# STM32H7R register map
File version: 1.0
CPU: CM7 r0p1, little endian, MPU, FPU, 4 interrupt priority bits
Registers are 32-bit, read-write, reset 0x0 unless marked. A register's access mark holds for its fields unless they carry their own. Offsets are from the block's base; [hi:lo] are bit positions; {n}, {i} and the like mark numbered series; 'fields as' and 'values as' point back to an identical list.

## LTDC — LTDC register block
Base 0x50001000
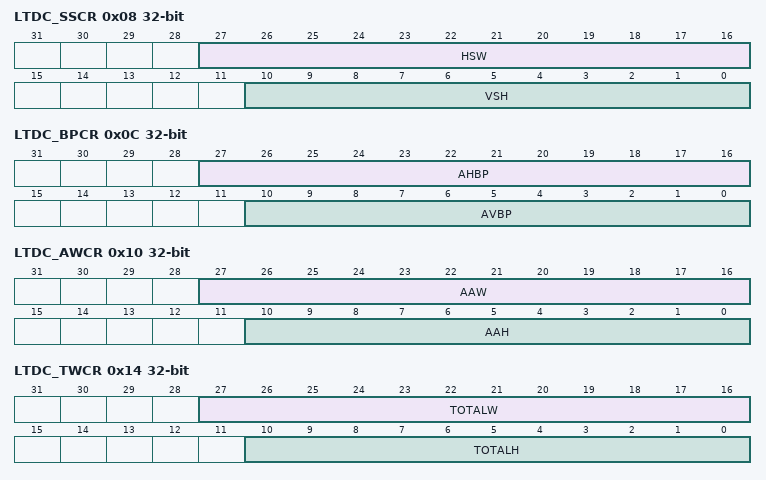
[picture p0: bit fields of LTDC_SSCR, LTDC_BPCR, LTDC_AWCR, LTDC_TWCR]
0x08 LTDC_SSCR — LTDC synchronization size configuration register
  [27:16] HSW — horizontal synchronization width (in units of pixel clock period) These bits define the number of Horizontal Synchronization pixel minus 1.
  [10:0] VSH — vertical synchronization height (in units of horizontal scan line) These bits define the vertical Synchronization height minus 1. It represents the number of horizontal synchronization lines.
0x0C LTDC_BPCR — LTDC back porch configuration register
  [27:16] AHBP — accumulated horizontal back porch (in units of pixel clock period) These bits define the accumulated horizontal back porch width that includes the horizontal synchronization and horizontal back porch pixels minus 1. The horizontal back porch is the period between horizontal synchronization going inactive and the start of the active display part of the next scan line.
  [10:0] AVBP — accumulated Vertical back porch (in units of horizontal scan line) These bits define the accumulated vertical back porch width that includes the vertical synchronization and vertical back porch lines minus 1. The vertical back porch is the number of horizontal scan lines at a start of frame to the start of the first active scan line of the next frame.
0x10 LTDC_AWCR — LTDC active width configuration register
  [27:16] AAW — accumulated active width (in units of pixel clock period) These bits define the accumulated active width which includes the horizontal synchronization, horizontal back porch and active pixels minus 1. The active width is the number of pixels in active display area of the panel scan line. Refer to device datasheet for maximum active width supported following maximum pixel clock.
  [10:0] AAH — accumulated active height (in units of horizontal scan line) These bits define the accumulated height which includes the vertical synchronization, vertical back porch and the active height lines minus 1. The active height is the number of active lines in the panel. Refer to device datasheet for maximum active height supported following maximum pixel clock.
0x14 LTDC_TWCR — LTDC total width configuration register
  [27:16] TOTALW — total width (in units of pixel clock period) These bits defines the accumulated total width which includes the horizontal synchronization, horizontal back porch, active width and horizontal front porch pixels minus 1.
  [10:0] TOTALH — total height (in units of horizontal scan line) These bits defines the accumulated height which includes the vertical synchronization, vertical back porch, the active height and vertical front porch height lines minus 1.
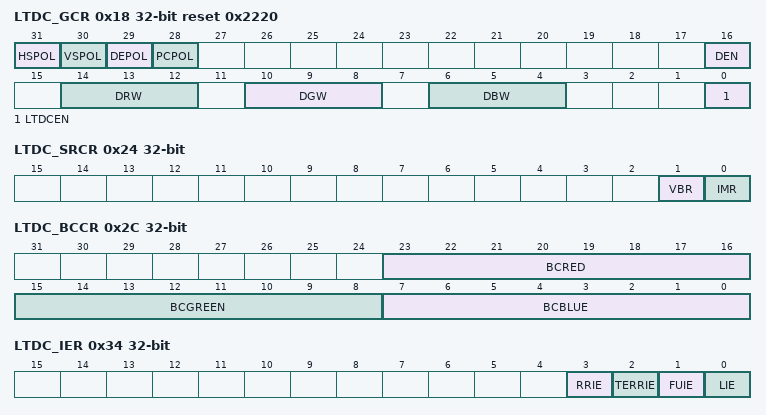
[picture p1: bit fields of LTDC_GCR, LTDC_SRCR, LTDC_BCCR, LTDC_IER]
0x18 LTDC_GCR access per field reset 0x2220 — LTDC global control register
  [31] HSPOL rw — horizontal synchronization polarity This bit is set and cleared by software.
    0=horizontal synchronization polarity is active low; 1=horizontal synchronization polarity is active high
  [30] VSPOL rw — vertical synchronization polarity This bit is set and cleared by software.
    0=vertical synchronization is active low; 1=vertical synchronization is active high
  [29] DEPOL rw — not data enable polarity This bit is set and cleared by software.
    0=not data enable polarity is active low; 1=not data enable polarity is active high
  [28] PCPOL rw — pixel clock polarity This bit is set and cleared by software.
    0=pixel clock polarity is active low; 1=pixel clock is active high
  [16] DEN rw — dither enable This bit is set and cleared by software.
    0=dither disabled; 1=dither enabled
  [14:12] DRW ro — dither red width These bits return the Dither Red Bits.
  [10:8] DGW ro — dither green width These bits return the dither green bits.
  [6:4] DBW ro — dither blue width These bits return the dither blue bits.
  [0] LTDCEN rw — LCD-TFT controller enable This bit is set and cleared by software.
    0=LTDC disabled; 1=LTDC enabled
0x24 LTDC_SRCR — LTDC shadow reload configuration register
  [1] VBR — vertical blanking reload This bit is set by software and cleared only by hardware after reload (it cannot be cleared through register write once it is set).
    0=no effect; 1=The shadow registers are reloaded during the vertical blanking period (at the beginning of the first line after the active display area)
  [0] IMR — immediate reload This bit is set by software and cleared only by hardware after reload.
    0=no effect; 1=The shadow registers are reloaded immediately
0x2C LTDC_BCCR — LTDC background color configuration register
  [23:16] BCRED — background color red value These bits configure the background red value.
  [15:8] BCGREEN — background color green value These bits configure the background green value.
  [7:0] BCBLUE — background color blue value These bits configure the background blue value.
0x34 LTDC_IER — LTDC interrupt enable register
  [3] RRIE — register reload interrupt enable This bit is set and cleared by software.
    0=register reload interrupt disable; 1=register reload interrupt enable
  [2] TERRIE — transfer error interrupt enable This bit is set and cleared by software.
    0=transfer error interrupt disable; 1=transfer error interrupt enable
  [1] FUIE — FIFO underrun interrupt enable This bit is set and cleared by software.
    0=FIFO underrun interrupt disable; 1=FIFO underrun Interrupt enable
  [0] LIE — line interrupt enable This bit is set and cleared by software.
    0=line interrupt disable; 1=line interrupt enable
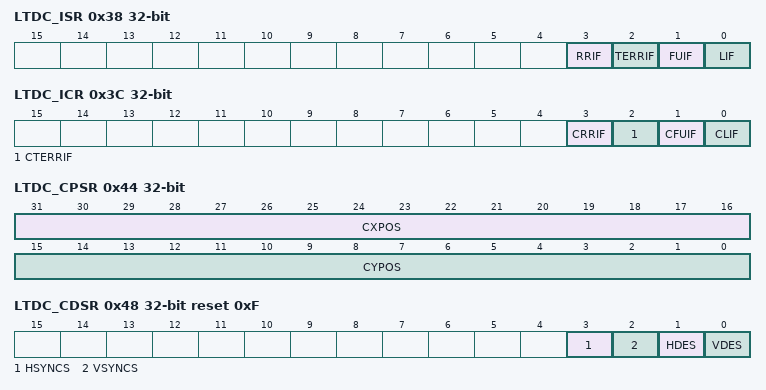
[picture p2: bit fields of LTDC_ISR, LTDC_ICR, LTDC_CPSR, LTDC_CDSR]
0x38 LTDC_ISR ro — LTDC interrupt status register
  [3] RRIF — register reload interrupt flag
    0=no register reload interrupt generated; 1=register reload interrupt generated when a vertical blanking reload occurs (and the first line after the active area is reached)
  [2] TERRIF — transfer error interrupt flag
    0=no transfer error interrupt generated; 1=transfer error interrupt generated when a bus error occurs
  [1] FUIF — FIFO underrun interrupt flag
    0=no FIFO underrun interrupt generated; 1=FIFO underrun interrupt generated, if one of the layer FIFOs is empty and pixel data is read from the FIFO
  [0] LIF — line interrupt flag
    0=no line interrupt generated; 1=line interrupt generated when a programmed line is reached
0x3C LTDC_ICR wo — LTDC interrupt clear register
  [3] CRRIF — clears register reload interrupt flag
    0=no effect; 1=clears the RRIF flag in the LTDC_ISR register
  [2] CTERRIF — clears the transfer error interrupt flag
    0=no effect; 1=clears the TERRIF flag in the LTDC_ISR register
  [1] CFUIF — clears the FIFO underrun interrupt flag
    0=no effect; 1=clears the FUDERRIF flag in the LTDC_ISR register
  [0] CLIF — clears the line interrupt flag
    0=no effect; 1=clears the LIF flag in the LTDC_ISR register
0x40 LTDC_LIPCR — LTDC line interrupt position configuration register
  [10:0] LIPOS — line interrupt position These bits configure the line interrupt position.
0x44 LTDC_CPSR ro — LTDC current position status register
  [31:16] CXPOS — current X position These bits return the current X position.
  [15:0] CYPOS — current Y position These bits return the current Y position.
0x48 LTDC_CDSR ro reset 0xF — LTDC current display status register
  [all] fields
    0=active low; 1=active high
  [3] HSYNCS — horizontal synchronization display status
  [2] VSYNCS — vertical synchronization display status
  [1] HDES — horizontal data enable display status
  [0] VDES — vertical data enable display status
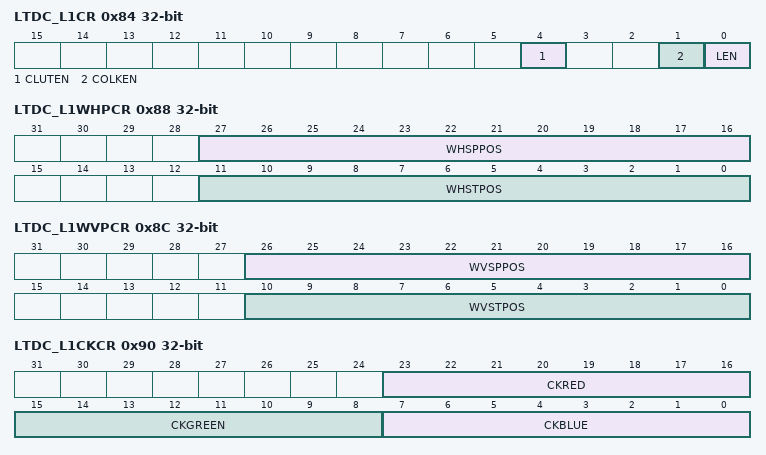
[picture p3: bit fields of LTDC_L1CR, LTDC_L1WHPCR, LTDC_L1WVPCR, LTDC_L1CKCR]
0x84 LTDC_L1CR — LTDC layer 1 control register
  [4] CLUTEN — color look-up table enable This bit is set and cleared by software. The CLUT is only meaningful for L8, AL44 and AL88 pixel format. Refer to Color look-up table (CLUT)
    0=color look-up table disable; 1=color look-up table enable
  [1] COLKEN — color keying enable This bit is set and cleared by software.
    0=color keying disable; 1=color keying enable
  [0] LEN — layer enable This bit is set and cleared by software.
    0=layer disable; 1=layer enable
0x88 LTDC_L1WHPCR — LTDC layer 1 window horizontal position configuration register
  [27:16] WHSPPOS — window horizontal stop position These bits configure the last visible pixel of a line of the layer window. WHSPPOS[11:0] must be more or equal to AHBP[11:0] bits + 1 (programmed in LTDC_BPCR register).
  [11:0] WHSTPOS — window horizontal start position These bits configure the first visible pixel of a line of the layer window. WHSTPOS[11:0] must be UNDER OR EQUAL AAW[11:0] bits (programmed in LTDC_AWCR register).
0x8C LTDC_L1WVPCR — LTDC layer 1 window vertical position configuration register
  [26:16] WVSPPOS — window vertical stop position These bits configure the last visible line of the layer window. WVSPPOS[10:0] must be more or equal to AVBP[10:0] bits + 1 (programmed in LTDC_BPCR register).
  [10:0] WVSTPOS — window vertical start position These bits configure the first visible line of the layer window. WVSTPOS[10:0] must be UNDER OR EQUAL AAH[10:0] bits (programmed in LTDC_AWCR register).
0x90 LTDC_L1CKCR — LTDC layer 1 color keying configuration register
  [23:16] CKRED — color key red value
  [15:8] CKGREEN — color key green value
  [7:0] CKBLUE — color key blue value
0x94 LTDC_L1PFCR — LTDC layer 1 pixel format configuration register
  [2:0] PF — pixel format These bits configure the pixel format
    0=ARGB8888; 1=RGB888; 2=RGB565; 3=ARGB1555; 4=ARGB4444; 5=L8 (8-bit luminance); 6=AL44 (4-bit alpha, 4-bit luminance); 7=AL88 (8-bit alpha, 8-bit luminance)
0x98 LTDC_L1CACR reset 0xFF — LTDC layer 1 constant alpha configuration register
  [7:0] CONSTA — constant alpha These bits configure the constant alpha used for blending. The constant alpha is divided by 255 by hardware. Example: if the programmed constant alpha is 0xFF, the constant alpha value is 255 / 255 = 1.
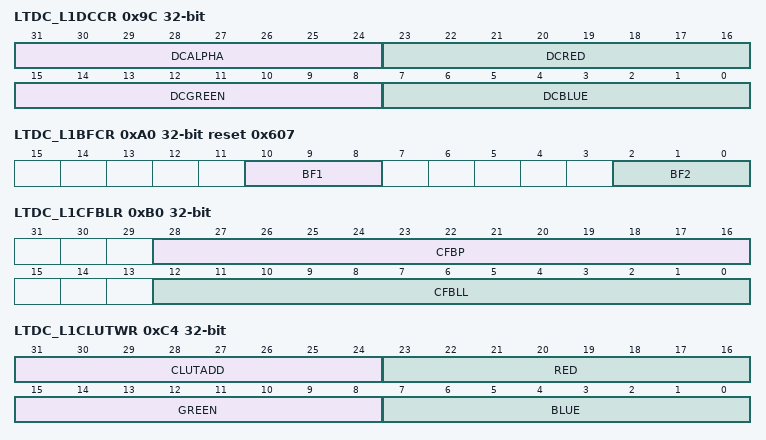
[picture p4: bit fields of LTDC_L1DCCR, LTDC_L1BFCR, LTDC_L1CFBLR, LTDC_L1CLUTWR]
0x9C LTDC_L1DCCR — LTDC layer 1 default color configuration register
  [31:24] DCALPHA — default color alpha These bits configure the default alpha value.
  [23:16] DCRED — default color red These bits configure the default red value.
  [15:8] DCGREEN — default color green These bits configure the default green value.
  [7:0] DCBLUE — default color blue These bits configure the default blue value.
0xA0 LTDC_L1BFCR reset 0x607 — LTDC layer 1 blending factors configuration register
  [10:8] BF1 — blending factor 1 These bits select the blending factor F1.
    {v}=FIELD Reserved (v=0..3); 4=constant alpha; 5=FIELD Reserved; 6=pixel alpha x constant alpha; 7=FIELD Reserved
  [2:0] BF2 — blending factor 2 These bits select the blending factor F2
    {v}=FIELD Reserved (v=0..4); 5=1 - constant alpha; 6=FIELD Reserved; 7=1 - (pixel alpha x constant alpha)
0xAC LTDC_L1CFBAR — LTDC layer 1 color frame buffer address register
  [31:0] CFBADD — color frame buffer start address These bits define the color frame buffer start address.
0xB0 LTDC_L1CFBLR — LTDC layer 1 color frame buffer length register
  [28:16] CFBP — color frame buffer pitch in bytes These bits define the pitch that is the increment from the start of one line of pixels to the start of the next line in bytes.
  [12:0] CFBLL — color frame buffer line length These bits define the length of one line of pixels in bytes + 7. The line length is computed as follows: active high width * number of bytes per pixel + 7.
0xB4 LTDC_L1CFBLNR — LTDC layer 1 color frame buffer line number register
  [10:0] CFBLNBR — frame buffer line number These bits define the number of lines in the frame buffer that corresponds to the active high width.
0xC4 LTDC_L1CLUTWR wo — LTDC layer 1 CLUT write register
  [31:24] CLUTADD — CLUT address These bits configure the CLUT address (color position within the CLUT) of each RGB value.
  [23:16] RED — red value These bits configure the red value.
  [15:8] GREEN — green value These bits configure the green value.
  [7:0] BLUE — blue value These bits configure the blue value.
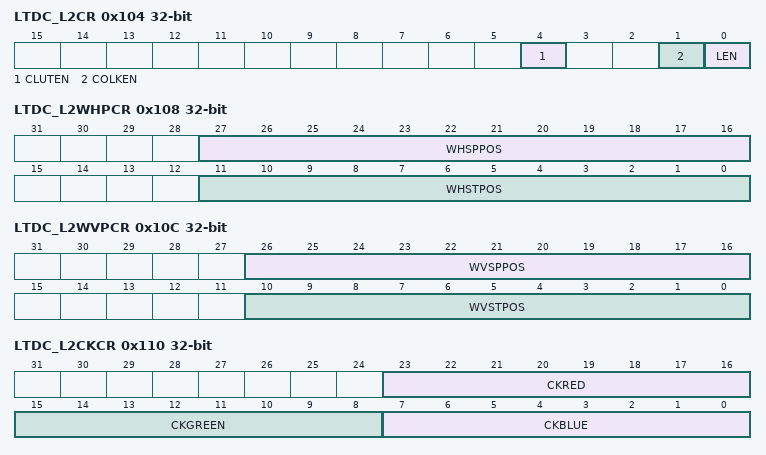
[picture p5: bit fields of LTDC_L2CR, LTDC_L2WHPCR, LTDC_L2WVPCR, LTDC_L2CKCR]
0x104 LTDC_L2CR — LTDC layer 2 control register
  fields as LTDC_L1CR
0x108 LTDC_L2WHPCR — LTDC layer 2 window horizontal position configuration register
  fields as LTDC_L1WHPCR
0x10C LTDC_L2WVPCR — LTDC layer 2 window vertical position configuration register
  fields as LTDC_L1WVPCR
0x110 LTDC_L2CKCR — LTDC layer 2 color keying configuration register
  fields as LTDC_L1CKCR
0x114 LTDC_L2PFCR — LTDC layer 2 pixel format configuration register
  fields as LTDC_L1PFCR
0x118 LTDC_L2CACR reset 0xFF — LTDC layer 2 constant alpha configuration register
  fields as LTDC_L1CACR
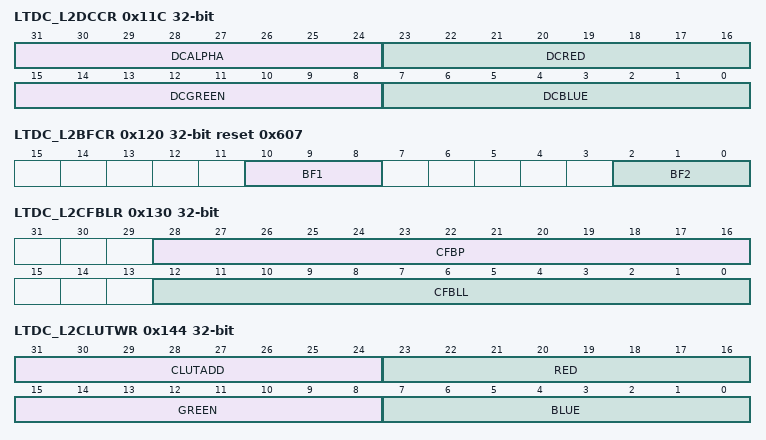
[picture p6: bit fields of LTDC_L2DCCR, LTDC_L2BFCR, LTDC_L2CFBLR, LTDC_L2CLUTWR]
0x11C LTDC_L2DCCR — LTDC layer 2 default color configuration register
  fields as LTDC_L1DCCR
0x120 LTDC_L2BFCR reset 0x607 — LTDC layer 2 blending factors configuration register
  fields as LTDC_L1BFCR
0x12C LTDC_L2CFBAR — LTDC layer 2 color frame buffer address register
  fields as LTDC_L1CFBAR
0x130 LTDC_L2CFBLR — LTDC layer 2 color frame buffer length register
  fields as LTDC_L1CFBLR
0x134 LTDC_L2CFBLNR — LTDC layer 2 color frame buffer line number register
  fields as LTDC_L1CFBLNR
0x144 LTDC_L2CLUTWR wo — LTDC layer 2 CLUT write register
  fields as LTDC_L1CLUTWR

## Notices in the file
Copyright (c) 2024 STMicroelectronics.
SPDX-License-Identifier: Apache-2.0
Licensed under the Apache License, Version 2.0 (the "License");
you may not use this file except in compliance with the License.
You may obtain a copy of the License at
http://www.apache.org/licenses/LICENSE-2.0
Unless required by applicable law or agreed to in writing, software
distributed under the License is distributed on an "AS IS" BASIS,
WITHOUT WARRANTIES OR CONDITIONS OF ANY KIND, either express or implied.
See the License for the specific language governing permissions and
limitations under the License.
